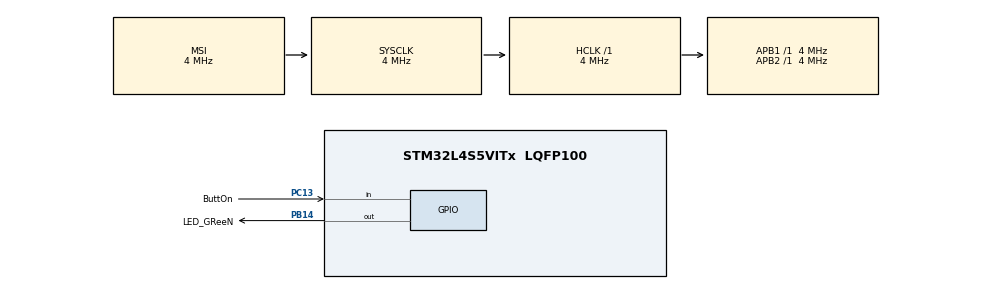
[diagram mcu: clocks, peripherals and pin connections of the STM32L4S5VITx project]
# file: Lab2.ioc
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ADC1.Channel-6\#ChannelRegularConversion=ADC_CHANNEL_VREFINT
ADC1.NbrOfConversionFlag=1
ADC1.OffsetNumber-6\#ChannelRegularConversion=ADC_OFFSET_NONE
ADC1.Rank-6\#ChannelRegularConversion=1
ADC1.SamplingTime-6\#ChannelRegularConversion=ADC_SAMPLETIME_640CYCLES_5
ADC1.master=1
Mcu.Family=STM32L4
Mcu.Name=STM32L4S5VITx
Mcu.Package=LQFP100
NVIC.PriorityGroup=NVIC_PRIORITYGROUP_4
PB14.GPIO_Label=LED_GReeN
PB14.Signal=GPIO_Output
PC13.GPIO_Label=ButtOn
PC13.Signal=GPIO_Input
ProjectManager.HeapSize=0x200
ProjectManager.StackSize=0x400
ProjectManager.TargetToolchain=STM32CubeIDE
RCC.ADCFreq_Value=80000000
RCC.AHBFreq_Value=4000000
RCC.APB1Freq_Value=4000000
RCC.APB1TimFreq_Value=4000000
RCC.APB2Freq_Value=4000000
RCC.APB2TimFreq_Value=4000000
RCC.CortexFreq_Value=4000000
RCC.HCLKFreq_Value=4000000
RCC.HSE_VALUE=8000000
RCC.HSI48_VALUE=48000000
RCC.HSI_VALUE=16000000
RCC.LSE_VALUE=32768
RCC.MSI_VALUE=4000000
RCC.PLLSAI1N=40
RCC.SYSCLKFreq_VALUE=4000000
RCC.USBFreq_Value=80000000
RCC.VCOOutputFreq_Value=32000000
VP_ADC1_TempSens_Input.Mode=IN-TempSens
VP_ADC1_Vref_Input.Mode=IN-Vrefint
board=custom

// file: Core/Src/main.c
/* USER CODE BEGIN Header */
/**
  ******************************************************************************
  * @file           : main.c
  * @brief          : Main program body
  ******************************************************************************
  * @attention
  *
  * <h2><center>&copy; Copyright (c) 2021 STMicroelectronics.
  * All rights reserved.</center></h2>
  *
  * This software component is licensed by ST under BSD 3-Clause license,
  * the "License"; You may not use this file except in compliance with the
  * License. You may obtain a copy of the License at:
  *                        opensource.org/licenses/BSD-3-Clause
  *
  ******************************************************************************
  */
/* USER CODE END Header */
#include "main.h"

/* USER CODE BEGIN PD */
#define TS_CAL1    ((uint16_t*)((uint32_t)0x1FFF75A8))
#define TS_CAL2   ((uint16_t*)((uint32_t)0x1FFF75CA))
#define VREFINT_CAL		((uint16_t*)((uint32_t)0x1FFF75AA))
/* USER CODE END PD */

ADC_HandleTypeDef hadc1;

void SystemClock_Config(void);
static void MX_GPIO_Init(void);
static void MX_ADC1_Init(void);

/* USER CODE BEGIN 0 */

//ADC Initialization function for changing the channel to VREFINT
static void MX_ADC1_InitVREF(void)
{
  ADC_ChannelConfTypeDef sConfig = {0};

  /** Configure Regular Channel
  */
  sConfig.Channel = ADC_CHANNEL_VREFINT;
  sConfig.Rank = ADC_REGULAR_RANK_1;
  sConfig.SamplingTime = ADC_SAMPLETIME_640CYCLES_5; //640.5 Cycles per sample --> Min sample time is 4us
  sConfig.SingleDiff = ADC_SINGLE_ENDED;
  sConfig.OffsetNumber = ADC_OFFSET_NONE;
  sConfig.Offset = 0;
  if (HAL_ADC_ConfigChannel(&hadc1, &sConfig) != HAL_OK)
  {
    Error_Handler();
  }

}

//ADC Initialization function for changing the channel to Temp Sensor
static void MX_ADC1_InitTS(void)
{
  ADC_ChannelConfTypeDef sConfig = {0};

  /** Configure Regular Channel
  */
  sConfig.Channel = ADC_CHANNEL_TEMPSENSOR;
  sConfig.Rank = ADC_REGULAR_RANK_1;
  sConfig.SamplingTime = ADC_SAMPLETIME_640CYCLES_5; //640.5 Cycles per sample --> Min sample time is 5us
  sConfig.SingleDiff = ADC_SINGLE_ENDED;
  sConfig.OffsetNumber = ADC_OFFSET_NONE;
  sConfig.Offset = 0;
  if (HAL_ADC_ConfigChannel(&hadc1, &sConfig) != HAL_OK)
  {
    Error_Handler();
  }

}

//Global variables watched in realtime with Live Expression viewer
float vref;
float temperature;
uint32_t data;

/* USER CODE END 0 */

int main(void)
{

  /* MCU Configuration--------------------------------------------------------*/

  /* Reset of all peripherals, Initializes the Flash interface and the Systick. */
  HAL_Init();

  /* Configure the system clock */
  SystemClock_Config();

  /* Initialize all configured peripherals */
  MX_GPIO_Init();
  MX_ADC1_Init();
  /* USER CODE BEGIN 2 */

  //Setting up our LED state machine and calibrating the ADC
  int LEDState = 0;
  HAL_ADCEx_Calibration_Start(&hadc1, ADC_SINGLE_ENDED);

  //A few parameters found in the datasheet, used for calculations
  float scaling = 3.3/3.0;
  float vref_charac = 3.0;

  /* USER CODE END 2 */

  /* Infinite loop */
  /* USER CODE BEGIN WHILE */
  while (1)
  {

	  //LED state machine
	  if (HAL_GPIO_ReadPin(ButtOn_GPIO_Port, ButtOn_Pin) == 0) {
		  LEDState = !LEDState;

		  if (LEDState == 0) {
			  HAL_GPIO_WritePin(LED_GReeN_GPIO_Port, LED_GReeN_Pin, GPIO_PIN_RESET);

			  //No LED light --> read data from VREFINT channel
			  MX_ADC1_InitVREF();
		  }
		  else if (LEDState == 1 ) {
			  HAL_GPIO_WritePin(LED_GReeN_GPIO_Port, LED_GReeN_Pin, GPIO_PIN_SET);

			  //Yes LED light --> read data from TEMP SENSOR channel
			  MX_ADC1_InitTS();
		  }

		  while(HAL_GPIO_ReadPin(ButtOn_GPIO_Port, ButtOn_Pin) == 0) {

		  }

	  }

	  //Poll the ADC
	  HAL_ADC_Start(&hadc1);
	  if (HAL_ADC_PollForConversion(&hadc1, 1000) == HAL_OK) { //Wait until conversion is complete
		  data = HAL_ADC_GetValue(&hadc1); //Obtain results of ADC conversion
	  }
	  HAL_ADC_Stop(&hadc1);

	  //Do appropriate calculations based on state of LED
	  if (LEDState == 0) {
	 	   //Calculate Vref+
	 	   vref = vref_charac*(uint32_t)*VREFINT_CAL/(float)data;

	  } else {
		   //Calculate temperature
	 	   temperature = 30 + (((float)data*scaling - (uint32_t)*TS_CAL1)*((float)((uint32_t)130 - (uint32_t)30)))/((float)(int32_t)((uint32_t)*TS_CAL2 - (uint32_t)*TS_CAL1));
	  }

    /* USER CODE END WHILE */

  }
}

void SystemClock_Config(void)
{
  RCC_OscInitTypeDef RCC_OscInitStruct = {0};
  RCC_ClkInitTypeDef RCC_ClkInitStruct = {0};
  RCC_PeriphCLKInitTypeDef PeriphClkInit = {0};

  /** Configure the main internal regulator output voltage
  */
  if (HAL_PWREx_ControlVoltageScaling(PWR_REGULATOR_VOLTAGE_SCALE1) != HAL_OK)
  {
    Error_Handler();
  }
  /** Initializes the RCC Oscillators according to the specified parameters
  * in the RCC_OscInitTypeDef structure.
  */
  RCC_OscInitStruct.OscillatorType = RCC_OSCILLATORTYPE_MSI;
  RCC_OscInitStruct.MSIState = RCC_MSI_ON;
  RCC_OscInitStruct.MSICalibrationValue = 0;
  RCC_OscInitStruct.MSIClockRange = RCC_MSIRANGE_6;
  RCC_OscInitStruct.PLL.PLLState = RCC_PLL_NONE;
  if (HAL_RCC_OscConfig(&RCC_OscInitStruct) != HAL_OK)
  {
    Error_Handler();
  }
  /** Initializes the CPU, AHB and APB buses clocks
  */
  RCC_ClkInitStruct.ClockType = RCC_CLOCKTYPE_HCLK|RCC_CLOCKTYPE_SYSCLK
                              |RCC_CLOCKTYPE_PCLK1|RCC_CLOCKTYPE_PCLK2;
  RCC_ClkInitStruct.SYSCLKSource = RCC_SYSCLKSOURCE_MSI;
  RCC_ClkInitStruct.AHBCLKDivider = RCC_SYSCLK_DIV1;
  RCC_ClkInitStruct.APB1CLKDivider = RCC_HCLK_DIV1;
  RCC_ClkInitStruct.APB2CLKDivider = RCC_HCLK_DIV1;

  if (HAL_RCC_ClockConfig(&RCC_ClkInitStruct, FLASH_LATENCY_0) != HAL_OK)
  {
    Error_Handler();
  }
  PeriphClkInit.PeriphClockSelection = RCC_PERIPHCLK_ADC;
  PeriphClkInit.AdcClockSelection = RCC_ADCCLKSOURCE_PLLSAI1;
  PeriphClkInit.PLLSAI1.PLLSAI1Source = RCC_PLLSOURCE_MSI;
  PeriphClkInit.PLLSAI1.PLLSAI1M = 1;
  PeriphClkInit.PLLSAI1.PLLSAI1N = 40;
  PeriphClkInit.PLLSAI1.PLLSAI1P = RCC_PLLP_DIV2;
  PeriphClkInit.PLLSAI1.PLLSAI1Q = RCC_PLLQ_DIV2;
  PeriphClkInit.PLLSAI1.PLLSAI1R = RCC_PLLR_DIV2;
  PeriphClkInit.PLLSAI1.PLLSAI1ClockOut = RCC_PLLSAI1_ADC1CLK;
  if (HAL_RCCEx_PeriphCLKConfig(&PeriphClkInit) != HAL_OK)
  {
    Error_Handler();
  }
}

static void MX_ADC1_Init(void)
{

  ADC_ChannelConfTypeDef sConfig = {0};

  /** Common config
  */
  hadc1.Instance = ADC1;
  hadc1.Init.ClockPrescaler = ADC_CLOCK_ASYNC_DIV1;
  hadc1.Init.Resolution = ADC_RESOLUTION_12B;
  hadc1.Init.DataAlign = ADC_DATAALIGN_RIGHT;
  hadc1.Init.ScanConvMode = ADC_SCAN_DISABLE;
  hadc1.Init.EOCSelection = ADC_EOC_SINGLE_CONV;
  hadc1.Init.LowPowerAutoWait = DISABLE;
  hadc1.Init.ContinuousConvMode = DISABLE;
  hadc1.Init.NbrOfConversion = 1;
  hadc1.Init.DiscontinuousConvMode = DISABLE;
  hadc1.Init.ExternalTrigConv = ADC_SOFTWARE_START;
  hadc1.Init.ExternalTrigConvEdge = ADC_EXTERNALTRIGCONVEDGE_NONE;
  hadc1.Init.DMAContinuousRequests = DISABLE;
  hadc1.Init.Overrun = ADC_OVR_DATA_PRESERVED;
  hadc1.Init.OversamplingMode = DISABLE;
  if (HAL_ADC_Init(&hadc1) != HAL_OK)
  {
    Error_Handler();
  }
  /** Configure Regular Channel
  */
  sConfig.Channel = ADC_CHANNEL_VREFINT;
  sConfig.Rank = ADC_REGULAR_RANK_1;
  sConfig.SamplingTime = ADC_SAMPLETIME_640CYCLES_5;
  sConfig.SingleDiff = ADC_SINGLE_ENDED;
  sConfig.OffsetNumber = ADC_OFFSET_NONE;
  sConfig.Offset = 0;
  if (HAL_ADC_ConfigChannel(&hadc1, &sConfig) != HAL_OK)
  {
    Error_Handler();
  }

}

static void MX_GPIO_Init(void)
{
  GPIO_InitTypeDef GPIO_InitStruct = {0};

  /* GPIO Ports Clock Enable */
  __HAL_RCC_GPIOC_CLK_ENABLE();
  __HAL_RCC_GPIOB_CLK_ENABLE();

  /*Configure GPIO pin Output Level */
  HAL_GPIO_WritePin(LED_GReeN_GPIO_Port, LED_GReeN_Pin, GPIO_PIN_RESET);

  /*Configure GPIO pin : ButtOn_Pin */
  GPIO_InitStruct.Pin = ButtOn_Pin;
  GPIO_InitStruct.Mode = GPIO_MODE_INPUT;
  GPIO_InitStruct.Pull = GPIO_NOPULL;
  HAL_GPIO_Init(ButtOn_GPIO_Port, &GPIO_InitStruct);

  /*Configure GPIO pin : LED_GReeN_Pin */
  GPIO_InitStruct.Pin = LED_GReeN_Pin;
  GPIO_InitStruct.Mode = GPIO_MODE_OUTPUT_PP;
  GPIO_InitStruct.Pull = GPIO_NOPULL;
  GPIO_InitStruct.Speed = GPIO_SPEED_FREQ_LOW;
  HAL_GPIO_Init(LED_GReeN_GPIO_Port, &GPIO_InitStruct);

}

void Error_Handler(void)
{
  __disable_irq();
  while (1)
  {
  }
}

/************************ (C) COPYRIGHT STMicroelectronics *****END OF FILE****/
